# nrf9220_application register map
Vendor: Nordic Semiconductor; Series: nRF92; File version: 1
CPU: CM33 r0p4, little endian, MPU, FPU, 3 interrupt priority bits, 480 interrupts, 4 SAU regions
Registers are 32-bit, read-write, reset 0x0 unless marked. A register's access mark holds for its fields unless they carry their own. Offsets are from the block's base; [hi:lo] are bit positions; lines under a group give offsets from that group; {n}, {i} and the like mark numbered series; 'fields as' and 'values as' point back to an identical list.

## GLOBAL_MRAMC110_NS — MRAM controller 0
Base 0x4F092000
Same registers: GLOBAL_MRAMC111_NS 0x4F093000, GLOBAL_MRAMC110_S 0x5F092000, GLOBAL_MRAMC111_S 0x5F093000
0x100 EVENTS_READY — Current operation is completed
  [0] EVENTS_READY
    0=NotGenerated (Event not generated); 1=Generated (Event generated)
0x104 EVENTS_READYNEXT — Ready to accept a new write operation
  [0] EVENTS_READYNEXT
    values as EVENTS_READY.EVENTS_READY
0x108 EVENTS_ECCERROR — ECC error detected but not corrected.
  [0] EVENTS_ECCERROR
    values as EVENTS_READY.EVENTS_READY
0x10C EVENTS_ECCERRORCORR — ECC error detected and corrected.
  [0] EVENTS_ECCERRORCORR
    values as EVENTS_READY.EVENTS_READY
0x110 EVENTS_TRIMCONFIGREQ — MRAM trim configuration request. The MRAMC is ready for the MRAM trim configuration.
  [0] EVENTS_TRIMCONFIGREQ
    values as EVENTS_READY.EVENTS_READY
0x114 EVENTS_ACCESSERR — MRAM access error.
  [0] EVENTS_ACCESSERR
    values as EVENTS_READY.EVENTS_READY
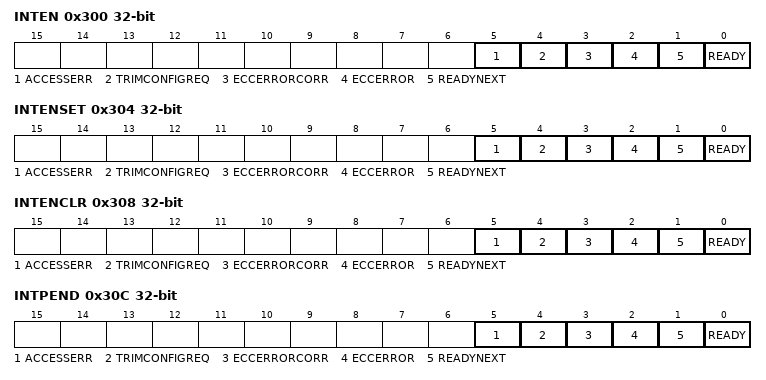
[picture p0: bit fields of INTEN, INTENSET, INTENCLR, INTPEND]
0x300 INTEN — Enable or disable interrupt
  [all] fields
    0=Disabled; 1=Enabled
  [5] ACCESSERR — Enable or disable interrupt for event ACCESSERR
  [4] TRIMCONFIGREQ — Enable or disable interrupt for event TRIMCONFIGREQ
  [3] ECCERRORCORR — Enable or disable interrupt for event ECCERRORCORR
  [2] ECCERROR — Enable or disable interrupt for event ECCERROR
  [1] READYNEXT — Enable or disable interrupt for event READYNEXT
  [0] READY — Enable or disable interrupt for event READY
0x304 INTENSET — Enable interrupt
  [all] fields
    on read: 0=Disabled (Read: Disabled); 1=Enabled (Read: Enabled) | on write: 1=Set (Enable)
  [5] ACCESSERR — Write '1' to enable interrupt for event ACCESSERR
  [4] TRIMCONFIGREQ — Write '1' to enable interrupt for event TRIMCONFIGREQ
  [3] ECCERRORCORR — Write '1' to enable interrupt for event ECCERRORCORR
  [2] ECCERROR — Write '1' to enable interrupt for event ECCERROR
  [1] READYNEXT — Write '1' to enable interrupt for event READYNEXT
  [0] READY — Write '1' to enable interrupt for event READY
0x308 INTENCLR — Disable interrupt
  [all] fields
    on read: 0=Disabled (Read: Disabled); 1=Enabled (Read: Enabled) | on write: 1=Clear (Disable)
  [5] ACCESSERR — Write '1' to disable interrupt for event ACCESSERR
  [4] TRIMCONFIGREQ — Write '1' to disable interrupt for event TRIMCONFIGREQ
  [3] ECCERRORCORR — Write '1' to disable interrupt for event ECCERRORCORR
  [2] ECCERROR — Write '1' to disable interrupt for event ECCERROR
  [1] READYNEXT — Write '1' to disable interrupt for event READYNEXT
  [0] READY — Write '1' to disable interrupt for event READY
0x30C INTPEND ro — Pending interrupts
  [all] fields
    on read: 0=NotPending (Read: Not pending); 1=Pending (Read: Pending)
  [5] ACCESSERR — Read pending status of interrupt for event ACCESSERR
  [4] TRIMCONFIGREQ — Read pending status of interrupt for event TRIMCONFIGREQ
  [3] ECCERRORCORR — Read pending status of interrupt for event ECCERRORCORR
  [2] ECCERROR — Read pending status of interrupt for event ECCERROR
  [1] READYNEXT — Read pending status of interrupt for event READYNEXT
  [0] READY — Read pending status of interrupt for event READY
0x400 READY ro — MRAMC current operation status.
  [0] READY — MRAMC is ready or busy
    0=Busy (MRAMC is busy); 1=Ready (Current operation is completed and MRAMC is ready)
0x404 READYNEXT ro — Ready next flag.
  [0] READYNEXT — MRAMC can accept a new write operation
    0=Busy (MRAMC cannot accept any write operation now); 1=Ready (MRAMC is ready to accept a new write operation)
0x410 ECC group — Unspecified
  0x00 ERROR — ECC Error status.
    [0] ECCERROR — ECC error detected for a read which could not be corrected. Write 0 to clear.
      0=NoEccError (ECC error not detected); 1=ECC error detected
  0x04 ERRORCORR — ECC error detected and corrected.
    [0] ERRORCORR — ECC error detected and corrected for a read. Write 0 to clear.
      0=NoEccError (ECC error not detected); 1=ErrorCorr (ECC error detected and corrected)
  0x08 ERRORADDR ro reset 0xFFFFFFFF — Address of the first ECC error that could not be corrected.
    [31:0] ERRORADDR — Address
  0x0C CORRADDR ro reset 0xFFFFFFFF — Address of the first ECC error that was corrected.
    [31:0] CORRADDR — Address
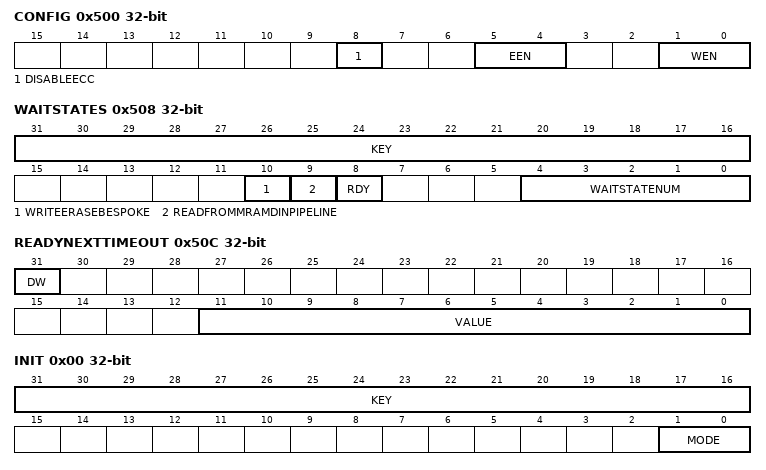
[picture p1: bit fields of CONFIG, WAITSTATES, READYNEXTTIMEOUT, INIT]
0x500 CONFIG — Configuration register
  [8] DISABLEECC — Disable ECC. It is enabled by default
    0=EnableECC; 1=DisableECC
  [5:4] EEN — Erase enable.
    0=DisableErase (Erase is disabled but read is allowed); 1=EnablePageErase (Erase page and read are allowed); 2=EnableWordErase (Erase word and read are allowed)
  [1:0] WEN — Write enable.
    0=DisableWrite (Write is disabled); 1=EnableNormalWrite (Normal write is enabled); 2=EnableDirectWrite (Direct write is enabled)
0x504 AUTOREADMODE — Automatically disables the write and erases on timeout and enters into read mode.
  [11:0] VALUE — Timeout value to disable write and erase.
0x508 WAITSTATES — Waitstates for MRAM read access
  [31:16] KEY — Key to enable the writing to this register.
    0=Disable the writing to this register; 0xA66D=Enable the writing to this register
  [10] WRITEERASEBESPOKE — Select the operational mode for the bespoke request
    0=RequestInMode (Send the bespoke signal when entering either write or erase mode, and release the request when exiting those modes.); 1=RequestFromConfig (Send the besopke request when a write or an erase is enabled in CONFIG register.)
  [9] READFROMMRAMDINPIPELINE — Register to enable or disable reading data pending to be committed to MRAM from the data input pipeline if the data at the requested read address is already present in the MRAM data input pipeline. Only applicable for direct write mode.
    0=Disable reading uncommitted data from MRAM data input pipeline; 1=Enable reading uncommitted data from MRAM data input pipeline. READYNEXTTIMEOUT.DW bit should also be set in order for this to work.
  [8] RDY — Use RDY (ready) signal from the MRAM macro in addition to waitstates specified above. The data is read which ever of waitstate or RDY signal comes first.
    0=Disable (Do not use RDY signal from the MRAM macro); 1=Enable (Use RDY signal from the MRAM macro)
  [4:0] WAITSTATENUM — Register to read the current number of waitstate for the MRAM access and set a new value
0x50C READYNEXTTIMEOUT — Preload timeout value for waiting for a next write
  [31] DW — Triggers a write to MRAMC macro on the ready next timeout in direct write mode (CONFIG.WEN = 2) and some data written into the internal write buffer.
    0=Disable (No write trigger); 1=Enable (Write trigger)
  [11:0] VALUE — Preload value
0x510 LOWAVGCURR group — Unspecified
  0x00 READ — Preload timeout value for low average current in case of read
    [11:0] VALUE — Preload value
  0x04 WRITE — Preload timeout value for low average current in case of write
    [11:0] VALUE — Preload value
  0x08 ERASE — Preload timeout value for low average current in case of erase
    [11:0] VALUE — Preload value
0x520 POWER group — Unspecified
  0x00 INIT — Initiates power up or down sequence.
    [31:16] KEY — Key to enable the writing to this register.
      values as WAITSTATES.KEY
    [1:0] MODE — Power mode.
      0=NoOperation (No change in power mode); 1=PowerUp (Triggers power up sequence. Ignored if MRAM is already in Active mode or Standby mode.); 2=PowerDown (Initiates power down sequence. Ignored if MRAM is already in MRAM_OFF mode.); 3=PowerDownTrimRet (Initiates power down sequence with trim retained. Ignored if MRAM is already in MRAM_OFF_TRIM_RETAIN mode.)
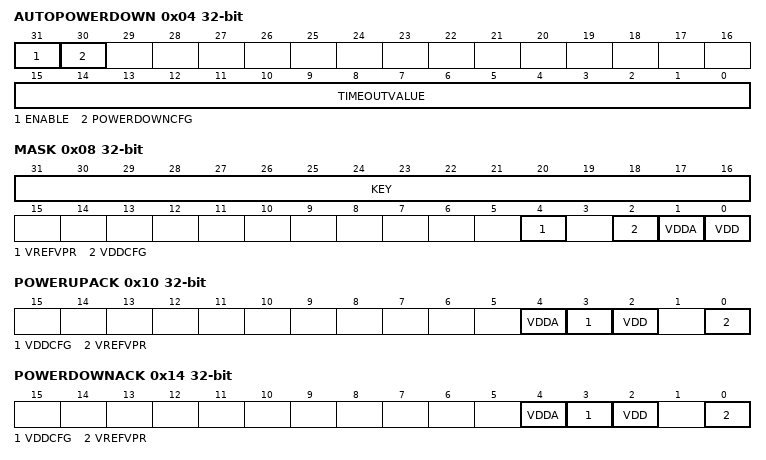
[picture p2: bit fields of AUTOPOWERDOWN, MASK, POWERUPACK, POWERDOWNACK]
  0x04 AUTOPOWERDOWN — Configures the automatic power down feature using the inactive time period of MRAM.
    [31] ENABLE — Enable the automatic power down feature.
      0=Disable the automatic power down feature; 1=Enable the automatic power down feature
    [30] POWERDOWNCFG — Power down mode when the timeout happens.
      0=MramOffTrimRetain (Power mode is MRAM_OFF_TRIM_RETAIN); 1=MramOff (Power mode is MRAM_OFF)
    [15:0] TIMEOUTVALUE — Timeout value for the power down.
  0x08 MASK — Mask for the various voltages supplies when initiating power up/down.
    [31:16] KEY — Key to enable the writing to this register.
      values as WAITSTATES.KEY
    [4] VREFVPR — Mask VREF and VPR
      0=NoOperation; 1=Mask VREF and VPR
    [2] VDDCFG — Mask VDD_CFG
      0=NoOperation; 1=Mask VDD_CFG
    [1] VDDA — Mask VDDA
      0=NoOperation; 1=Mask VDDA
    [0] VDD — Mask VDD
      0=NoOperation; 1=Mask VDD
  0x0C STATUS ro — Status of the power up/down sequence.
    [3:0] STATE — The current power up/down state.
      0=Off (MRAM is OFF); 1=PowerUpSeq (MRAM power up sequence is active); 2=TrimConfigSeq (Request for the MRAM trim configuration.); 3=TrimConfigWait (Waiting for the MRAM trim configuration to complete.); 4=TrimConfigDone (The MRAM trim configuration to completed (This is momentary state).); 5=Standby (MRAM is in standby mode.); 6=Active (MRAM is in active mode (or in standby mode)); 7=PowerDownSeq (MRAM power down sequence is active); 8=OffTrimRetain (MRAM is OFF with trim configuration in retain)
  0x10 POWERUPACK ro — Status of the power control signals acknowledgement during power up sequence.
    [all] fields
      0=Busy; 1=Ready
    [4] VDDA — Waiting for VDDA up ACK or not
    [3] VDDCFG — Waiting for VDD_CFG up ACK or not
    [2] VDD — Waiting for VDD up ACK or not
    [0] VREFVPR — Waiting for VREF and VPR up ACK or not
  0x14 POWERDOWNACK ro — Status of the power control signals acknowledgement during power down sequence.
    [all] fields
      0=Busy; 1=Ready
    [4] VDDA — Waiting for VDDA down ACK or not
    [3] VDDCFG — Waiting for VDD_CFG down ACK or not
    [2] VDD — Waiting for VDD down ACK or not
    [0] VREFVPR — Waiting for VREF and VPR down ACK or not
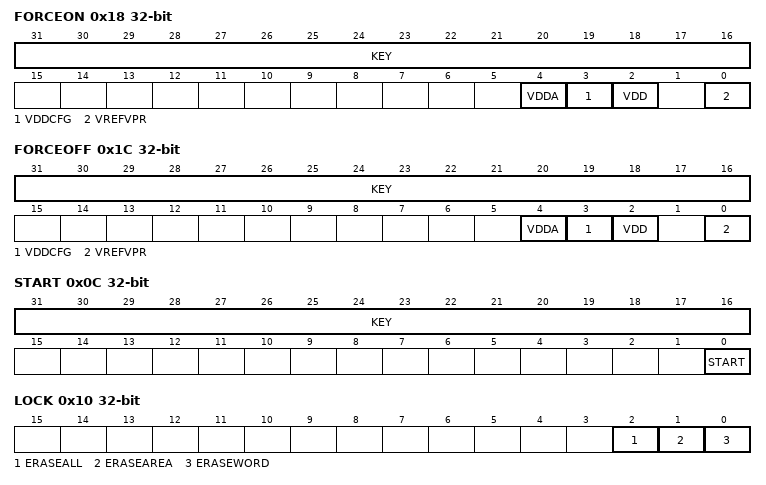
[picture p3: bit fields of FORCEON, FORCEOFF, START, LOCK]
  0x18 FORCEON — Force ON the power supply.
    [31:16] KEY — Key to enable the writing to this register.
      values as WAITSTATES.KEY
    [4] VDDA — Force ON the VDDA supply
      0=NoOperation (No Force ON.); 1=ForceOn
    [3] VDDCFG — Force ON the VDD_CFG supply
      0=NoOperation (No Force ON.); 1=ForceOn
    [2] VDD — Force ON the VDD supply
      0=NoOperation (No Force ON.); 1=ForceOn
    [0] VREFVPR — Force ON the VREF and VPR supply
      0=NoOperation (No Force ON.); 1=ForceOn
  0x1C FORCEOFF — Force OFF the power supply.
    [31:16] KEY — Key to enable the writing to this register.
      values as WAITSTATES.KEY
    [4] VDDA — Force OFF the VDDA supply
      0=NoOperation (No Force OFF.); 1=ForceOff
    [3] VDDCFG — Force OFF the VDD_CFG supply
      0=NoOperation (No Force OFF.); 1=ForceOff
    [2] VDD — Force OFF the VDD supply
      0=NoOperation (No Force OFF.); 1=ForceOff
    [0] VREFVPR — Force OFF the VREF and VPR supply
      0=NoOperation (No Force OFF.); 1=ForceOff
0x540 TRIM group — Unspecified
  0x00 DATAIN reset 0xFFFFFFFF — Data to be written to the MRAM trim configuration.
    [31:0] DATAIN — Data
  0x04 DATAOUT ro — Data read from the MRAM trim configuration.
    [31:0] DATAOUT — Data
  0x08 COUNT reset 0x20 — Number of bits in the current data to be written to and read from the trim configuration.
    [5:0] COUNT — Number of bits to be written.
  0x0C START — Start shifting data for trim configuration.
    [31:16] KEY — Key to enable the writing to this register.
      values as WAITSTATES.KEY
    [0] START — Start trim configuration
      0=NoOperation; 1=Start trim config
  0x10 READY ro reset 0x1 — Status of shifting the MRAM trim configuration data.
    [0] READY — Shifting the MRAM trim configuration data is in progress or not.
      0=Busy (Shifting the MRAM trim configuration data is in progress.); 1=Ready for shifting the next MRAM trim configuration data
  0x14 DONE — This register is used to indicate to the MRAMC that the whole MRAM trim configuration data write is completed.
    [31:0] TRIMCOMPLETED — Trim configuration is completed.
      on read: 0=TrimUnknown (Read: Trim configuration is unknown); 1=TrimCompleted (Read: Trim configuration data write is completed.) | on write: 0xA66DA66D=TrimComplete (Write: Trim configuration data write is complete.); 0=NoOperation (Write ignored for all other values than 0xA66DA66D.)
0x560 ERASE group — Unspecified
  0x00 ERASEWORD — Register for erasing a word in the MRAM main block.
    [31:0] ERASEWORD — Address of the word that needs to be erased.
  0x04 SIZE — Size for erasing an area in the MRAM main block
    [18:0] SIZE — Number of MRAM words to be erased using ERASE.ERASEAREA.
  0x08 ERASEAREA — Register for erasing an area in the MRAM main block
    [31:0] ERASEAREA — Start address of the area to be erased.
  0x0C ERASEALL wo — Register for erasing whole MRAM main block and the first NVR page
    [0] ERASEALL — Erase whole MRAM and the first NVR page. The other NVR pages are not erased.
      0=NoOperation; 1=Erase (Start erase of chip)
  0x10 LOCK — Locking the erase registers.
    [all] fields
      0=Disabled (Lock disabled.); 1=Enabled (Lock enabled.)
    [2] ERASEALL — Lock for ERASE.ERASEALL.
    [1] ERASEAREA — Lock for ERASE.ERASEAREA.
    [0] ERASEWORD — Lock for ERASE.ERASEWORD.
0x580 CONFIGNVR group — Unspecified
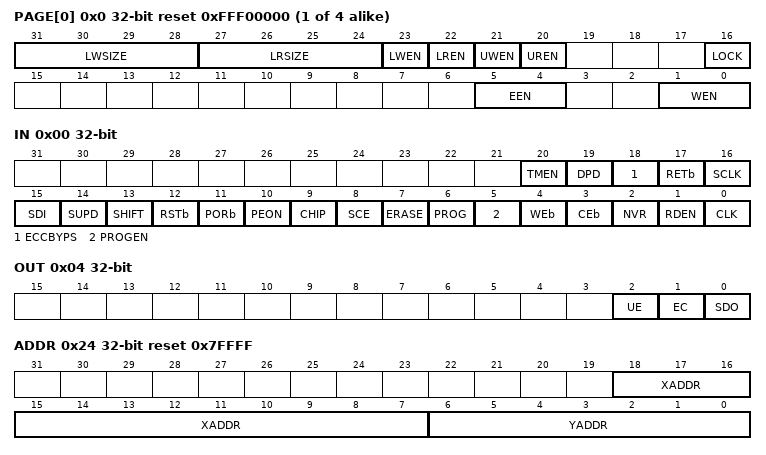
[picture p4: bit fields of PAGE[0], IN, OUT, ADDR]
  {0x0+4j} PAGE[{j}] (j=0..3) reset 0xFFF00000 — Description collection: Configuration register for NVR page n
    [31:28] LWSIZE — Size of part of the lower 2KB memory in the NVR page to disable write access
    [27:24] LRSIZE — Size of part of the lower 2KB memory in the NVR page to disable read access
    [23] LWEN write-0-clears — Enable write access to the lower range of the NVR page, as defined by LWSIZE
      0=Disabled (Write is disabled.); 1=Enabled (Write is enabled)
    [22] LREN write-0-clears — Enable read access to the lower range of the NVR page, as defined by LRSIZE
      0=Disabled (Read is disabled.); 1=Enabled (Read is enabled)
    [21] UWEN write-0-clears — Enable write access to the upper part of NVR page, where the upper part size is NVR page size - 2KB
      values as LWEN
    [20] UREN write-0-clears — Enable read access to the upper part of NVR page, where the upper part size is NVR page size - 2KB
      0=Disabled (Read is disabled.); 1=Enabled (Read is enabled)
    [16] LOCK write-1-sets — Enables the lock for this register.
      0=LockDisabled (Lock is disabled); 1=LockEnabled (Lock is enabled)
    [5:4] EEN — Erase enable.
      values as CONFIG.EEN
    [1:0] WEN — Write enable.
      values as CONFIG.WEN
0x600 TEST group — Unspecified
  0x00 TESTMODE — Register for entering test mode. Refer to the MRAM test flow documentation for more details.
    [15:0] TESTMODE — Register for entering test mode. This register does not return the same value as written.
      on read: 0=NORMAL (Read: Not in test-mode.); 1=Read: In TESTMODE1; 2=Read: In TESTMODE2 | on write: 0=SetNORMAL (Write: Sets NORMAL mode.); 0xBCDE=SetTESTMODE1 (Write: Sets TESTMODE1. Enables the mass erase.); 0xABCD=SetTESTMODE2 (Write: Sets TESTMODE2. Used for production tests.)
  0x04 LOCKTESTMODE — Enables the lock for the TESTMODE
    [31:0] EnableLock — Enables the lock for TESTMODE.
      on read: 0=LockDisabled (Read: TESTMODE is not locked); 1=LockEnabled (Read: TESTMODE is locked) | on write: 0x10CC10CC=EnableLock (Write: Enables the lock (Ignores any other value written))
0x608 TESTMODE1 group — Unspecified
  0x00 MASSERASE wo — Self-timed mass-erase operation.
    [1:0] MASSERASE
      3=EVERYTHING (Erase everything in the MRAM including all NVR pages); 2=MAIN (Erase only the main block); 1=NOOPERATION1; 0=NOOPERATION0
0x610 TESTMODE2 group — Unspecified
  0x00 MRAM group — Unspecified
    0x00 IN — Writes to the input control signals to the MRAM. Read to this registers reads back the last written value.
      [20] TMEN — Test Mode Enable
      [19] DPD — Deep Power Down
      [18] ECCBYPS — Bypass ECC Encoder and Decoder
      [17] RETb — Trim Configuration Register Retention (active low)
      [16] SCLK — Trim Configuration Clock
      [15] SDI — Trim Configuration Input
      [14] SUPD — Trim Configuration Upload
      [13] SHIFT — Trim Configuration Shift
      [12] RSTb — Trim Configuration Register Reset (active low)
      [11] PORb — Power On Reset (active low)
      [10] PEON — Read within program/erase
      [9] CHIP — Chip Erase
      [8] SCE — Sector Erase
      [7] ERASE — Erase signal
      [6] PROG — Program signal
      [5] PROGEN — Program Enable
      [4] WEb — Write Enable
      [3] CEb — Chip Enable
      [2] NVR — Select NVR pages/sectors
      [1] RDEN — Read Enable
      [0] CLK — Clock for synchronous Read
    0x04 OUT ro — The output control signals from the MRAM
      [2] UE — ECC Unrecoverable Error
      [1] EC — ECC Error Correction
      [0] SDO — Trim Configuration Register Output
    0x08 DONE ro — The DONE signal of the MRAM
      [0] DONE — Program/Erase Status
    0x0C RDY ro — The RDY signal of the MRAM
      [0] RDY — Read Status
  {0x10+4j} DATA[{j}] (j=0..3) — Description collection: Data word n to/from MRAM data in/out bus.
    [31:0] TESTDATA — Returns data from the MRAM data out bus on reading. Sets the data to the MRAM data in bus on writing.
  0x20 DATAECC — ECC bits to/from MRAM data in/out bus.
    [13:0] ECC — Returns ECC bits from the MRAM data out bus on reading. Sets the ECC bits to the MRAM data in bus on writing.
  0x24 ADDR reset 0x7FFFF — Address bits of the MRAM address bus. The register is updated when the auto-increment is done.
    [18:7] XADDR — Control the XADDR lines
    [6:0] YADDR — Control the YADDR lines. The YADDR is incremented on auto-increment and the XADDR is incremented by one when the YADDR overflow during increment.
  {0x28+4j} DATAINC[{j}] (j=0..3) — Description collection: Same as DATA but post-increments address after the read from the bus.
    [31:0] DATA — Read or write data.
  0x38 DATAECCINC — Same as DATAECC but post-increments ADDR after the read from the bus.
    [13:0] ECC — ECC bits.
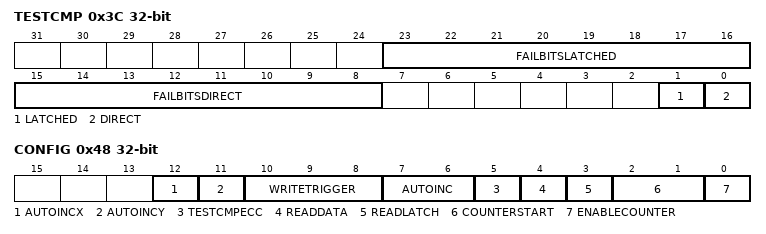
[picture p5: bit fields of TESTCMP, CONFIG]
  0x3C TESTCMP ro — Compares the MRAM data with DATA and DATAECC register content. Post-increments the address after the read based on TESTMODE2.CONFIG.AUTOINC.
    [23:16] FAILBITSLATCHED — Number of bits that does not match while comparing the latched data.
    [15:8] FAILBITSDIRECT — Number of bits that does not match while comparing the direct data.
    [1] LATCHED — Compares with the last latched data.
      0=Equal (The last latched data from MRAM bus and DATA and DATAECC register content are equal); 1=NotEqual (The last latched data from MRAM bus and DATA and DATAECC register content are different)
    [0] DIRECT — Reads and compares with MRAM data lines directly to DATA and DATAECC register content. If the CLK is high, then the CLK is set low, the address is incremented based on TESTMODE2.CONFIG.AUTOINC register and then the CLK is set high. During this, the tCKL and tAS timing are taken care by the MRAMC.
      0=Equal (Data read directly from MRAM bus and the DATA and DATAECC register content are equal); 1=NotEqual (Data read directly from MRAM bus and the DATA and DATAECC register content are different)
  0x40 COUNTERRELOAD — Configures the counter reload value. The counter is reloaded and starts counting from the CLK/PROGEN rising edge.
    [13:0] VALUE — Counter reload value.
  0x44 COUNTERRUN ro — Returns the state (counting or not) of the counter
    [0] RUNNING — Returns the state of the counter
      0=NotRunning (Counter is not running); 1=Running (Counter is running)
  0x48 CONFIG — TESTMODE2 Configuration
    [12] AUTOINCX — Controls the X address auto-increment feature when AUTOINC is 0
      0=NoIncrement (X Address auto-incrementing is disabled); 1=Increment1 (X Address auto-increment by one MRAM word, if AUTOINC is 0)
    [11] AUTOINCY — Controls the Y address auto-increment feature when AUTOINC is 0
      0=NoIncrement (Y Address auto-incrementing is disabled); 1=Increment1 (Y Address auto-increment by one MRAM word, if AUTOINC is 0)
    [10:8] WRITETRIGGER — Configuration for write trigger
      0=NoOperation (Write pulse handled manually.); {v}=DATAWORD{v-1} (Writing to DATA[{v-1}] or DATAINC[{v-1}] triggers write pulse) (v=1..4); 5=DATAECC (Writing to DATAECC or DATAECCINC triggers write to pulse)
    [7:6] AUTOINC — Controls the address auto-increment feature
      0=NoIncrement (Address auto-incrementing is disabled); 1=Increment1 (Address auto-increment by one MRAM word); 2=Increment2 (Address auto-increment by two MRAM words)
    [5] TESTCMPECC — Configuration for TESTCMP to exclude ECC or not while comparison
      0=Include (Compare both corresponding DATA and DATAECC with the direct/latched MRAM data); 1=Exclude (Compare only corresponding DATA with the direct/latched MRAM data)
    [4] READDATA — Configuration for the read to DATA, DATAINC, DATAECC and DATAECCINC, and TESTCMP
      0=Direct (Read the data directly from the MRAM data bus); 1=Latched (Read the last latched data from the MRAM data bus)
    [3] READLATCH — Configuration for latching the read/compare data
      0=RDY (Latch the read data on the next rising edge on RDY after CLK going high); 1=CounterTimeout (Latch the read data when the counter expires after CLK going high)
    [2:1] COUNTERSTART — Counter start configuration
      0=NoOperation (The counter is not active); 1=CLK (The counter start on rising edge of CLK); 2=PROGEN (The counter start on rising edge of PROGEN)
    [0] ENABLECOUNTER
      0=Disabled (Counter is disabled); 1=Enabled (Counter is enabled)
  0x4C TMOEN — Enable the pin multiplexing for TMO[2:0] pins of the MRAM macro
    [0] ENABLE — Enable or disable the TMO[2:0] pin multiplexing with analog IO pads.
      0=Disable multiplexing; 1=Enable multiplexing
  0x50 BURSTWORDSNUM — Number of words for burst read or write
    [18:0] WORDS — Number of words for burst read or write.
  0x54 BURSTMODESTAT ro — The burst mode operation status.
    [1:0] DONE — The burst mode operation is completed.
      0=NotActive (Burst mode operation not active); 1=Running (Burst mode is running); 2=Done (The last burst mode operation is completed); 3=Error (The last burst mode operation is completed with errors for read operation)
  0x58 ONEBITERR — Number of one bit error words detected while compare in the last burst mode read operation.
    [18:0] COUNT — Number of words with one bit errors.
  0x5C TWOBITSERR — Number of two bit errors words detected while compare in the last burst mode read operation.
    [18:0] COUNT — Number of words with one bit errors.
  0x60 MANYBITSERR — Number of more than two bit errors words detected while compare in the last burst mode read operation.
    [18:0] COUNT — Number of words with more than two bit errors.
  0x64 ONEBITERRTHR — Threshold in terms of number of one bit error words to end the burst mode read operation with error.
    [10:0] COUNT — Number of words with one bit errors.
  0x68 TWOBITSERRTHR — Threshold in terms of number of two bits error words to end the burst mode read operation with error.
    [10:0] COUNT — Number of words with two bits errors.
  0x6C MANYBITSERRTHR — Threshold in terms of number of more than two bits error words to end the burst mode read operation with error.
    [10:0] COUNT — Number of words with more than two bits errors.
